# G32R501 register map
Vendor: Geehy Semiconductor Co., Ltd.; Series: G32R5; File version: 1.0
CPU: CM55 r0p1, little endian, MPU, FPU, double-precision FPU, DSP, VTOR, 4 interrupt priority bits
Registers are 32-bit, read-write, reset 0x0 unless marked. A register's access mark holds for its fields unless they carry their own. Offsets are from the block's base; [hi:lo] are bit positions; {n}, {i} and the like mark numbered series.

## CFGSMS — Configurable Static Memory Subsystem(CFGSMS)
Base 0x50010800
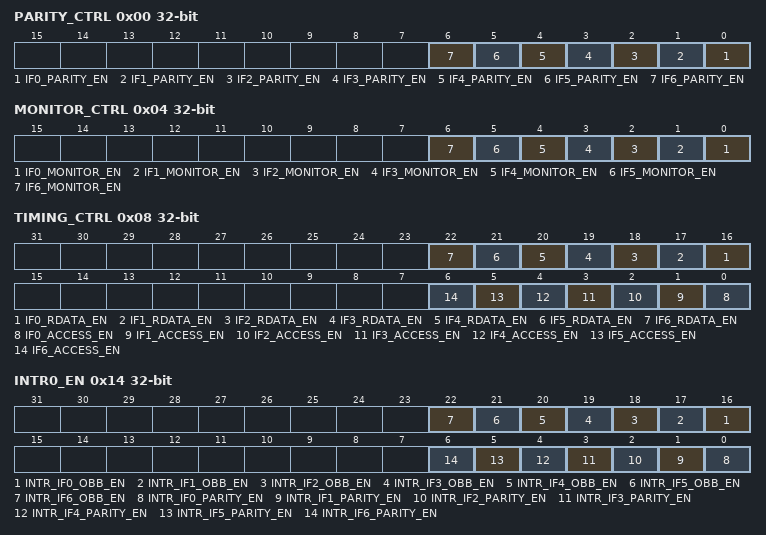
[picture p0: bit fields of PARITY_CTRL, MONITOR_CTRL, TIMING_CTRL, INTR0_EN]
0x00 PARITY_CTRL — Parity Control Register
  [n] IF{n}_PARITY_EN (n=0..6) — Parity Enable
0x04 MONITOR_CTRL — Monitor Control Register
  [n] IF{n}_MONITOR_EN (n=0..6) — Monitor Enable
0x08 TIMING_CTRL — Timing Control Register
  [n+16] IF{n}_RDATA_EN (n=0..6) — Read Data Enable
  [n] IF{n}_ACCESS_EN (n=0..6) — Access Enable
0x10 KEY_CFG — Key Configure Register
  [7:0] KEY_RGN — Key Range
0x14 INTR0_EN — Interrupt Enable Register 0
  [n+16] INTR_IF{n}_OBB_EN (n=0..6) — Out of Bank Bounds Interrupt Enable
  [n] INTR_IF{n}_PARITY_EN (n=0..6) — Data Parity Interrupt Enable
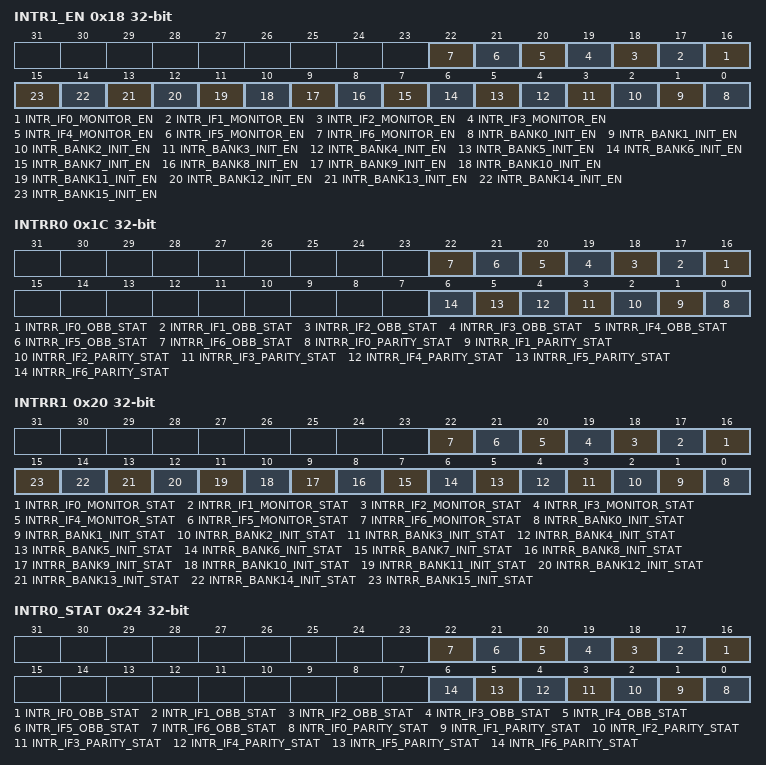
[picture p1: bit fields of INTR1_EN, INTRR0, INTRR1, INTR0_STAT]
0x18 INTR1_EN — Interrupt Enable Register 1
  [n+16] INTR_IF{n}_MONITOR_EN (n=0..6) — Monitor Interrupt Enable
  [n] INTR_BANK{n}_INIT_EN (n=0..15) — Bank Initiate Interrupt Enable
0x1C INTRR0 — Interrupt Raw Register 0
  [n+16] INTRR_IF{n}_OBB_STAT (n=0..6) — Out of Bank Bounds Interrupt Raw State
  [n] INTRR_IF{n}_PARITY_STAT (n=0..6) — Parity Interrupt Raw State
0x20 INTRR1 — Interrupt Raw Register 1
  [n+16] INTRR_IF{n}_MONITOR_STAT (n=0..6) — Monitor Interrupt Raw State
  [n] INTRR_BANK{n}_INIT_STAT (n=0..15) — Bank Initiate Interrupt Raw State
0x24 INTR0_STAT ro — Interrupt Status Register 0
  [n+16] INTR_IF{n}_OBB_STAT (n=0..6) — Out of Bank Bounds Interrupt State Register
  [n] INTR_IF{n}_PARITY_STAT (n=0..6) — Parity Interrupt State Register
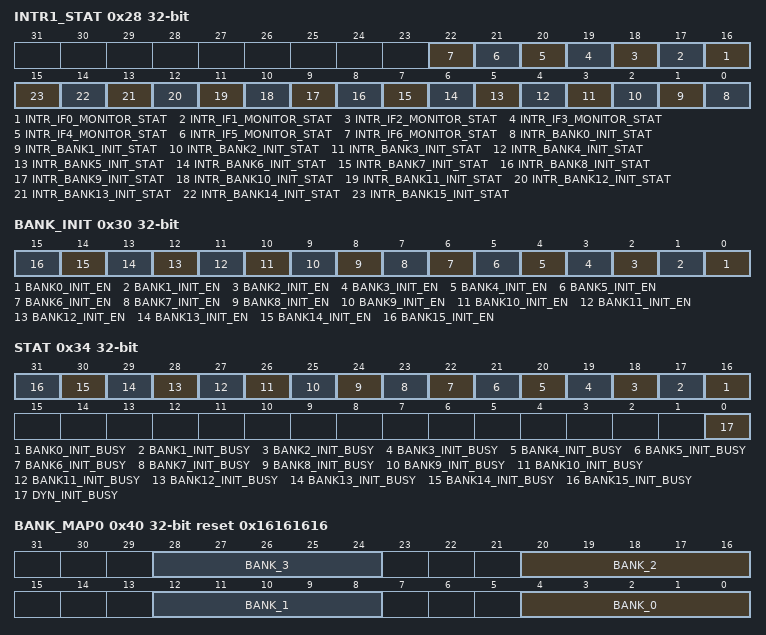
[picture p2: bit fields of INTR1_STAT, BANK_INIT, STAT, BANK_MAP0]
0x28 INTR1_STAT ro — Interrupt Status Register 1
  [n+16] INTR_IF{n}_MONITOR_STAT (n=0..6) — Monitor Interrupt State Register
  [n] INTR_BANK{n}_INIT_STAT (n=0..15) — Bank Initiate Interrupt State Register
0x2C BANK_CFG — Bank Configure Register
  [0] BANK_CFG_MODE — Bank Mode Configure
0x30 BANK_INIT — Bank Initiate Register
  [n] BANK{n}_INIT_EN (n=0..15) — Bank Initiate Enable
0x34 STAT ro — Status Register
  [n+16] BANK{n}_INIT_BUSY (n=0..15) — Bank Initiate Busy
  [0] DYN_INIT_BUSY — Dynamic Initiate Busy
0x40 BANK_MAP0 ro reset 0x16161616 — Bank Map Register 0
  [8n+4:8n] BANK_{n} (n=0..3)
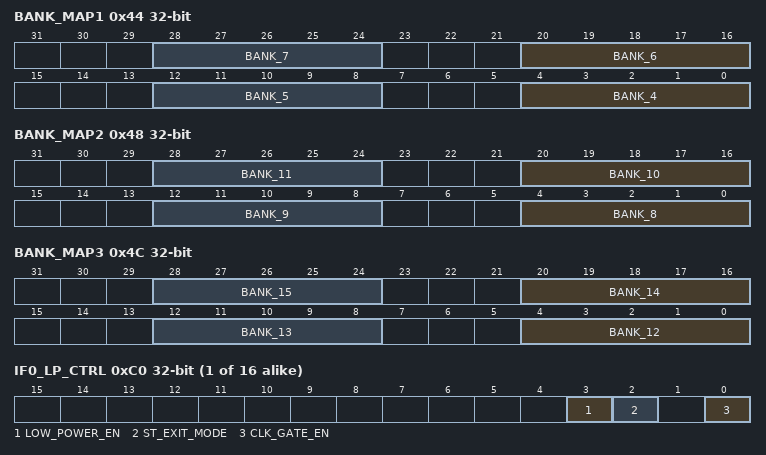
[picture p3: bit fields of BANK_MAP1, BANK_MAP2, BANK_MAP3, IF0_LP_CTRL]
0x44 BANK_MAP1 — Bank Map Register 1
  [8n-28:8n-32] BANK_{n} (n=4..7)
0x48 BANK_MAP2 — Bank Map Register 2
  [8n-60:8n-64] BANK_{n} (n=8..11)
0x4C BANK_MAP3 — Bank Map Register 3
  [8n-92:8n-96] BANK_{n} (n=12..15)
{0x80+4i} IF{i}_MONITOR_ADDR (i=0..15) — IF{i} Monitor Address Register
  [31:0] MONITOR_ADDR — Monitor Address
{0xC0+4i} IF{i}_LP_CTRL (i=0..15) — IF{i} Low Power Control Register
  [3] LOW_POWER_EN — Low Power Enable
  [2] ST_EXIT_MODE — Exit STOP Mode
  [0] CLK_GATE_EN — Clock Gate Enable
{0x100+4i} IF{i}_LP_CNT0 reset 0x3F (i=0..6) — Interface{i} Low Power Access Period Register-0
  [7:0] ENTER_LS_CYC — Enter Low-power Mode Cycle
{0x100+4i} IF{i}_LP_CNT0 reset 0x3F (i=7..15) — IF{i} Low Power Access Period Register-0
  [7:0] ENTER_LS_CYC — Enter Low-power Mode Cycle
{0x140+4i} IF{i}_LP_CNT1 reset 0x10000 (i=0..6) — Interface{i} Low Power Access Period Register-1
  [23:16] LS_SETUP_CYC — Setup cycle after Exiting Low Power Mode
{0x140+4i} IF{i}_LP_CNT1 reset 0x10000 (i=7..15) — IF{i} Low Power Access Period Register-1
  [23:16] LS_SETUP_CYC — Setup cycle after Exiting Low Power Mode
{0x180+4i} IF{i}_PARITY_ERR_DATA ro (i=0..6) — Interface{i} Parity Error Data Register
  [31:0] PARITY_DATA
{0x180+4i} IF{i}_PARITY_ERR_DATA ro (i=7..15) — IF{i} Parity Error Data Register
  [31:0] PARITY_DATA
{0x1C0+4i} IF{i}_PARITY_ERR_ADDR ro (i=0..6) — Interface{i} Parity Error Address Register
  [31:0] PARITY_ADDR
{0x1C0+4i} IF{i}_PARITY_ERR_ADDR ro (i=7..15) — IF{i} Parity Error Address Register
  [31:0] PARITY_ADDR
{0x200+4i} IF{i}_PARITY_ERR_INFO ro (i=0..6) — Interface{i} Parity Error Information Register
  [3:0] PARITY_INFO — Parity Information
{0x200+4i} IF{i}_PARITY_ERR_INFO ro (i=7..15) — IF{i} Parity Error Information Register
  [3:0] PARITY_INFO — Parity Information
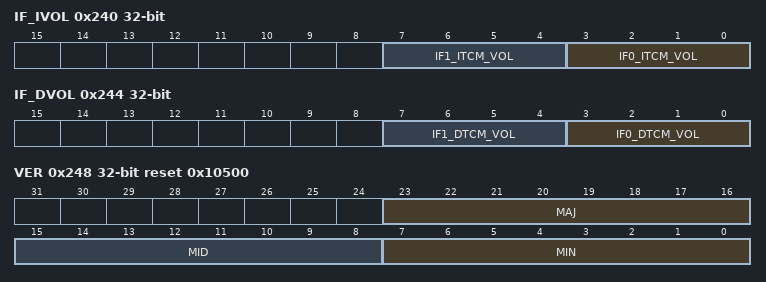
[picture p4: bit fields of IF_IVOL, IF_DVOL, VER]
0x240 IF_IVOL — IF ITCM Volume Register
  [4n+3:4n] IF{n}_ITCM_VOL (n=0..1) — ITCM Volume
0x244 IF_DVOL — IF DTCM Volume Register
  [4n+3:4n] IF{n}_DTCM_VOL (n=0..1) — DTCM Volume
0x248 VER ro reset 0x10500 — Version Register
  [23:16] MAJ — Major revision
  [15:8] MID — Middle revision
  [7:0] MIN — Minor revision
